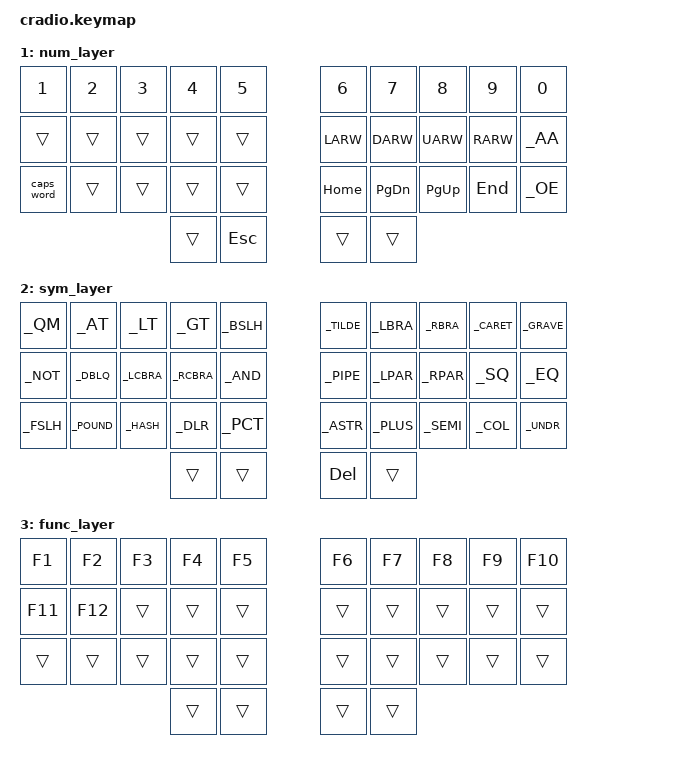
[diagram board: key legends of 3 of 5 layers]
// Copyright (c) 2022 The ZMK Contributors
// SPDX-License-Identifier: MIT

#include <behaviors.dtsi>
#include <dt-bindings/zmk/keys.h>
#include <dt-bindings/zmk/bt.h>
#include "keycodes.h"

// Home row mods macro
#define HRML(k1,k2,k3,k4) &ht LSHFT k1  &ht LCTRL k2  &ht LALT k3  &ht LGUI k4
#define HRMR(k1,k2,k3,k4) &ht RGUI k1  &ht RALT k2  &ht RCTRL k3  &ht RSHFT k4

#define NUM 1
#define SYM 2
#define FUN 3
#define SYS 4

#define BT_PROFILES &bt BT_SEL 0 &bt BT_SEL 1 &bt BT_SEL 2 &trans &trans// &bt BT_SEL 3 &bt BT_SEL 4

/ {
    behaviors {
        ht: hold_tap {
            label = "hold_tap";
            compatible = "zmk,behavior-hold-tap";
            #binding-cells = <2>;
            flavor = "tap-preferred";
            tapping-term-ms = <220>;
            quick-tap-ms = <150>;
            global-quick-tap;
            bindings = <&kp>, <&kp>;
        };
    };

    combos {
        compatible = "zmk,combos";
				// both left thumb keys
				combo_settings {
						timeout-ms = <300>;
						key-positions = <30 31>;
						bindings = <&mo SYS>;
				};
				combo_esc {
						timeout-ms = <250>;
						key-positions = <3 4>;
						layers = <0>;
						bindings = <&kp ESC>;
				};
				combo_del {
						timeout-ms = <250>;
						key-positions = <5 6>;
						layers = <0>;
						bindings = <&kp DELETE>;
				};
    };

    conditional_layers {
        compatible = "zmk,conditional-layers";
        tri_layer {
            if-layers = <NUM SYM>;
            then-layer = <FUN>;
        };
    };

    keymap {
        compatible = "zmk,keymap";
        default_layer {
            bindings = <
        //╭──────────┬──────────┬──────────┬──────────┬──────────╮   ╭──────────┬──────────┬──────────┬──────────┬──────────╮
        //│  Q       │  W       │  E       │  R       │  T       │   │  Y       │  U       │  I       │  O       │  P       │
            &kp Q      &kp W      &kp E      &kp R      &kp T          &kp Y      &kp U      &kp I      &kp O      &kp P
        //├──────────┼──────────┼──────────┼──────────┼──────────┤   ├──────────┼──────────┼──────────┼──────────┼──────────┤
        //│  A       │  S       │  D       │  F       │  G       │   │  H       │  J       │  K       │  L       │ Æ        │
            HRML(A,        S,         D,         F)     &kp G          &kp H      HRMR(J,        K,         L,        _AE)
        //├──────────┼──────────┼──────────┼──────────┼──────────┤   ├──────────┼──────────┼──────────┼──────────┼──────────┤
        //│  Z       │  X       │  C       │  V       │  B       │   │  N       │  M       │ , <      │ . >      │ / ?      │
            &kp Z      &kp X      &kp C      &kp V      &kp B          &kp N      &kp M      &kp COMMA  &kp DOT    &kp FSLH
        //╰──────────┴──────────┴──────────┼──────────┼──────────┤   ├──────────┼──────────┼──────────┴──────────┴──────────╯
                                            &lt SYM TAB &kp SPACE     &kp BSPC   &lt NUM ENTER
        //                                 ╰──────────┴──────────╯   ╰──────────┴──────────╯
            >;
        };

        num_layer {
            bindings = <
        //╭──────────┬──────────┬──────────┬──────────┬──────────╮   ╭──────────┬──────────┬──────────┬──────────┬──────────╮
        //│  1       │  2       │  3       │  4       │  5       │   │  6       │  7       │  8       │  9       │  0       │
            &kp N1     &kp N2     &kp N3     &kp N4     &kp N5         &kp N6     &kp N7     &kp N8     &kp N9     &kp N0
        //├──────────┼──────────┼──────────┼──────────┼──────────┤   ├──────────┼──────────┼──────────┼──────────┼──────────┤
        //│          │          │          │          │          │   │ LEFT     │ DOWN     │ UP       │ RIGHT    │  Å       │
            &trans    &trans     &trans     &trans     &trans         &kp LARW   &kp DARW   &kp UARW   &kp RARW   &kp _AA
        //├──────────┼──────────┼──────────┼──────────┼──────────┤   ├──────────┼──────────┼──────────┼──────────┼──────────┤
        //│ CAPS     │          │          │          │          │   │ HOME     │ PAGE DN  │ PAGE UP  │ END      │  Ø       │
           &caps_word  &trans     &trans     &trans     &trans         &kp HOME   &kp PG_DN  &kp PG_UP  &kp END    &kp _OE
        //╰──────────┴──────────┴──────────┼──────────┼──────────┤   ├──────────┼──────────┼──────────┴──────────┴──────────╯
                                            &trans     &kp ESC        &trans     &trans
        //                                 ╰──────────┴──────────╯   ╰──────────┴──────────╯
            >;
        };

        sym_layer {
            bindings = <
        //╭──────────┬──────────┬──────────┬──────────┬──────────╮   ╭──────────┬──────────┬──────────┬──────────┬──────────╮
        //│  ?       │  @       │  <       │  >       │  /       │   │  ~       │  [       │  ]       │ ^        │  `       │
            &kp _QM   &kp _AT     &kp _LT   &kp _GT     &kp _BSLH     &kp _TILDE  &kp _LBRA  &kp _RBRA &kp _CARET &kp _GRAVE
        //├──────────┼──────────┼──────────┼──────────┼──────────┤   ├──────────┼──────────┼──────────┼──────────┼──────────┤
        //│  !       │  "       │  {       │  }       │  &       │   │  |       │  (       │  )       │  '       │  =       │
           &kp _NOT   &kp _DBLQ  &kp _LCBRA &kp _RCBRA  &kp _AND      &kp _PIPE   &kp _LPAR &kp _RPAR   &kp _SQ   &kp _EQ
        //├──────────┼──────────┼──────────┼──────────┼──────────┤   ├──────────┼──────────┼──────────┼──────────┼──────────┤
        //│ \        │  £       │  #       │ $        │  %       │   │ *        │  +       │  ;       │  :       │ _        │
           &kp _FSLH  &kp _POUND &kp _HASH  &kp _DLR   &kp _PCT        &kp _ASTR  &kp _PLUS &kp _SEMI  &kp _COL   &kp _UNDR
        //╰──────────┴──────────┴──────────┼──────────┼──────────┤   ├──────────┼──────────┼──────────┴──────────┴──────────╯
                                             &trans     &trans         &kp DELETE &trans
        //                                 ╰──────────┴──────────╯   ╰──────────┴──────────╯
            >;
        };

        func_layer {
            bindings = <
        //╭──────────┬──────────┬──────────┬──────────┬──────────╮   ╭──────────┬──────────┬──────────┬──────────┬──────────╮
        //│ F1       │ F2       │ F3       │ F4       │ F5       │   │ F6       │ F7       │ F8       │ F9       │ F10      │
            &kp F1     &kp F2     &kp F3     &kp F4     &kp F5         &kp F6     &kp F7     &kp F8     &kp F9     &kp F10
        //├──────────┼──────────┼──────────┼──────────┼──────────┤   ├──────────┼──────────┼──────────┼──────────┼──────────┤
        //│ F11      │ F12      │          │          │          │   │          │          │          │          │          │
            &kp F11    &kp F12    &trans     &trans     &trans         &trans    &trans     &trans     &trans     &trans
        //├──────────┼──────────┼──────────┼──────────┼──────────┤   ├──────────┼──────────┼──────────┼──────────┼──────────┤
        //│          │          │          │          │          │   │          │          │          │          │          │
           &trans     &trans     &trans     &trans     &trans         &trans     &trans     &trans     &trans     &trans
        //╰──────────┴──────────┴──────────┼──────────┼──────────┤   ├──────────┼──────────┼──────────┴──────────┴──────────╯
                                            &trans     &trans         &trans     &trans
        //                                 ╰──────────┴──────────╯   ╰──────────┴──────────╯
            >;
        };

        sys_layer {
            bindings = <
        //╭──────────┬──────────┬──────────┬──────────┬──────────╮   ╭──────────┬──────────┬──────────┬──────────┬──────────╮
        //│PROFILE 0 │PROFILE 1 │PROFILE 2 │PROFILE 3 │PROFILE 4 │   │          │          │          │          │ CLEAR BT │
                                BT_PROFILES                           &trans     &trans     &trans     &trans     &bt BT_CLR
        //├──────────┼──────────┼──────────┼──────────┼──────────┤   ├──────────┼──────────┼──────────┼──────────┼──────────┤
        //│ RESET    │          │          │          │          │   │          │          │          │          │  RESET   │
           &sys_reset &trans     &trans     &trans     &trans         &trans     &trans     &trans     &trans     &sys_reset
        //├──────────┼──────────┼──────────┼──────────┼──────────┤   ├──────────┼──────────┼──────────┼──────────┼──────────┤
        //│BOOTLOADER│          │          │          │          │   │          │          │          │          │BOOTLOADER│
           &bootloader &trans     &trans   &trans     &trans         &trans     &trans     &trans     &trans     &bootloader
        //╰──────────┴──────────┴──────────┼──────────┼──────────┤   ├──────────┼──────────┼──────────┴──────────┴──────────╯
                                             &trans     &trans         &trans     &trans
        //                                 ╰──────────┴──────────╯   ╰──────────┴──────────╯
            >;
        };
    };
};
